CM_ "IMPORT _community.dbc";
CM_ "IMPORT _honda_common.dbc";
CM_ "IMPORT _nidec_common.dbc";
CM_ "IMPORT _lkas_hud_5byte.dbc";
CM_ "IMPORT _nidec_scm_group_a.dbc";
CM_ "IMPORT _steering_sensors_b.dbc";
CM_ "IMPORT _gearbox_common.dbc";

CM_ "2017-2020 Acura MDX (3rd gen, Nidec) with serial (LIN) steering, driven through an LKAS/CAN adapter board";
CM_ "Same layout as acura_ilx_2016_can (used by the Pilot 2016-22), except STEERING_CONTROL and STEER_STATUS,";
CM_ "which are exchanged with the LKAS/CAN adapter board (LINInterfaceV2 firmware) on the camera bus (bus 2) instead of an EPS.";

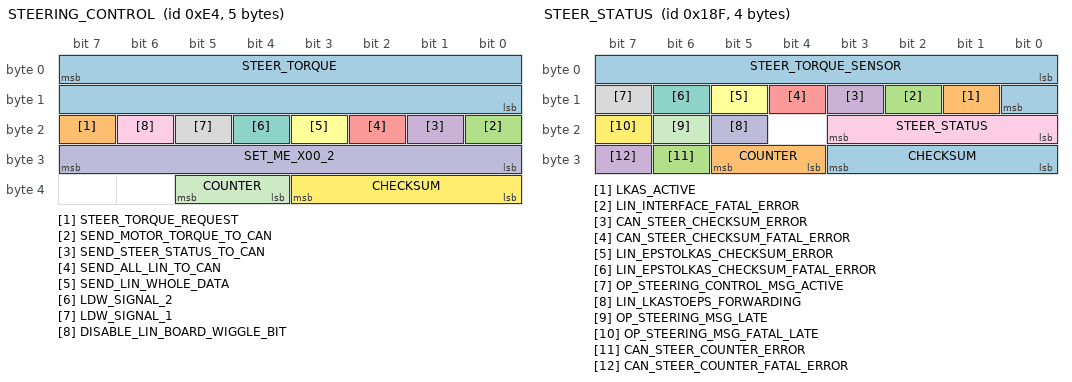
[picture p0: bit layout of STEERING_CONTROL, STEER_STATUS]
BO_ 228 STEERING_CONTROL: 5 ADAS
 SG_ STEER_TORQUE : 7|16@0- (1,0) [-3840|3840] "" EPS
 SG_ STEER_TORQUE_REQUEST : 23|1@0+ (1,0) [0|1] "" EPS
 SG_ SEND_MOTOR_TORQUE_TO_CAN : 16|1@0+ (1,0) [0|1] "" XXX
 SG_ SEND_STEER_STATUS_TO_CAN : 17|1@0+ (1,0) [0|1] "" XXX
 SG_ SEND_ALL_LIN_TO_CAN : 18|1@0+ (1,0) [0|1] "" XXX
 SG_ SEND_LIN_WHOLE_DATA : 19|1@0+ (1,0) [0|1] "" XXX
 SG_ LDW_SIGNAL_2 : 20|1@0+ (1,0) [0|1] "" XXX
 SG_ LDW_SIGNAL_1 : 21|1@0+ (1,0) [0|1] "" XXX
 SG_ DISABLE_LIN_BOARD_WIGGLE_BIT : 22|1@0+ (1,0) [0|1] "" XXX
 SG_ SET_ME_X00_2 : 31|8@0+ (1,0) [0|0] "" EPS
 SG_ COUNTER : 37|2@0+ (1,0) [0|3] "" EPS
 SG_ CHECKSUM : 35|4@0+ (1,0) [0|15] "" EPS

BO_ 399 STEER_STATUS: 4 EPS
 SG_ STEER_TORQUE_SENSOR : 0|9@1- (1,0) [-256|256] "" EON
 SG_ LKAS_ACTIVE : 9|1@0+ (1,0) [0|1] "" XXX
 SG_ LIN_INTERFACE_FATAL_ERROR : 10|1@0+ (1,0) [0|1] "" XXX
 SG_ CAN_STEER_CHECKSUM_ERROR : 11|1@0+ (1,0) [0|1] "" XXX
 SG_ CAN_STEER_CHECKSUM_FATAL_ERROR : 12|1@0+ (1,0) [0|1] "" XXX
 SG_ LIN_EPSTOLKAS_CHECKSUM_ERROR : 13|1@0+ (1,0) [0|1] "" XXX
 SG_ LIN_EPSTOLKAS_CHECKSUM_FATAL_ERROR : 14|1@0+ (1,0) [0|1] "" XXX
 SG_ OP_STEERING_CONTROL_MSG_ACTIVE : 15|1@0+ (1,0) [0|1] "" XXX
 SG_ STEER_STATUS : 16|4@1+ (1,0) [0|15] "" EON
 SG_ LIN_LKASTOEPS_FORWARDING : 21|1@0+ (1,0) [0|1] "" XXX
 SG_ OP_STEERING_MSG_LATE : 22|1@0+ (1,0) [0|1] "" XXX
 SG_ OP_STEERING_MSG_FATAL_LATE : 23|1@0+ (1,0) [0|1] "" XXX
 SG_ CHECKSUM : 27|4@0+ (1,0) [0|15] "" EON
 SG_ COUNTER : 29|2@0+ (1,0) [0|3] "" EON
 SG_ CAN_STEER_COUNTER_ERROR : 30|1@0+ (1,0) [0|1] "" XXX
 SG_ CAN_STEER_COUNTER_FATAL_ERROR : 31|1@0+ (1,0) [0|1] "" XXX

BO_ 521 LIN_DATA_IN: 8 XXX
 SG_ BIG_STEER : 0|4@1+ (1,0) [0|15] "" XXX
 SG_ UNK_SIGNAL : 4|1@0+ (1,0) [0|1] "" XXX
 SG_ LITTLE_STEER : 12|5@0+ (1,0) [0|31] "" XXX
 SG_ LKAS_ENABLED : 13|1@0+ (1,0) [0|1] "" XXX
 SG_ UNK_LDW_SIGNAL2 : 20|1@0+ (1,0) [0|1] "" XXX
 SG_ UNK_LDW_SIGNAL1 : 21|1@0+ (1,0) [0|1] "" XXX
 SG_ LKAS_ENABLED_INVERT : 22|1@0+ (1,0) [0|1] "" XXX
 SG_ BIG_DRIVER_TORQUE : 24|4@1+ (1,0) [0|15] "" XXX
 SG_ LIN_EPS_B0_O4 : 28|1@0+ (1,0) [0|1] "" XXX
 SG_ EPS_TO_LKAS_COUNTER_BIT : 29|1@0+ (1,0) [0|1] "" XXX
 SG_ SMALL_DRIVER_TORQUE : 36|5@0+ (1,0) [0|31] "" XXX
 SG_ LKAS_ON_FROM_EPS : 37|1@0+ (1,0) [0|1] "" XXX
 SG_ LIN_EPS_B1_O6 : 38|1@0+ (1,0) [0|1] "" XXX
 SG_ LIN_EPS_B2_O0_2 : 40|3@1+ (1,0) [0|7] "" XXX
 SG_ BIG_MOTOR_TORQUE : 45|3@0- (1,0) [0|7] "" XXX
 SG_ LKAS_ON_FROM_EPS_INVERT : 46|1@0+ (1,0) [0|1] "" XXX
 SG_ SMALL_MOTOR_TORQUE : 54|7@0+ (1,0) [0|127] "" XXX
 SG_ CHECKSUM : 59|4@0+ (1,0) [0|15] "" XXX
 SG_ COUNTER : 61|2@0+ (1,0) [0|3] "" XXX

CM_ SG_ 228 SEND_MOTOR_TORQUE_TO_CAN "LIN board option bits (byte 2, bits 0-6); openpilot leaves them 0";
CM_ SG_ 228 DISABLE_LIN_BOARD_WIGGLE_BIT "1 disables the board's LSB wiggle of the LIN steer value";
CM_ SG_ 399 STEER_TORQUE_SENSOR "driver torque, sign inverted by the board so left is positive";
CM_ SG_ 399 STEER_STATUS "bits 0-2: EPS LIN byte 2 bits 0-2, bit 3: EPS LIN byte 0 bit 4. 7 = driver overpowering LKAS: openpilot must drop the steer request (temporary fault), or the camera latches FCM/LKAS problem until restart";
CM_ SG_ 399 OP_STEERING_CONTROL_MSG_ACTIVE "set when the board is receiving STEERING_CONTROL (0xE4)";
CM_ SG_ 521 LKAS_ENABLED "raw LIN data, sent by the board while openpilot is not steering";

VAL_ 399 STEER_STATUS 11 "fault_1" 7 "driver_override" 2 "lkas_fatal_error" 1 "no_torque_alert_1" 0 "normal" ;
